# STM32N645 register map
File version: 1.0
CPU: CM55 r0p1, little endian, no MPU, FPU, vendor SysTick, 8 interrupt priority bits
Registers are 32-bit, read-write, reset 0x0 unless marked. A register's access mark holds for its fields unless they carry their own. Offsets are from the block's base; [hi:lo] are bit positions; {n}, {i} and the like mark numbered series.

## HASH — HASH register bank (full SHA-2/SHA-3)
Base 0x44020400
Same registers: HASH_S 0x54020400
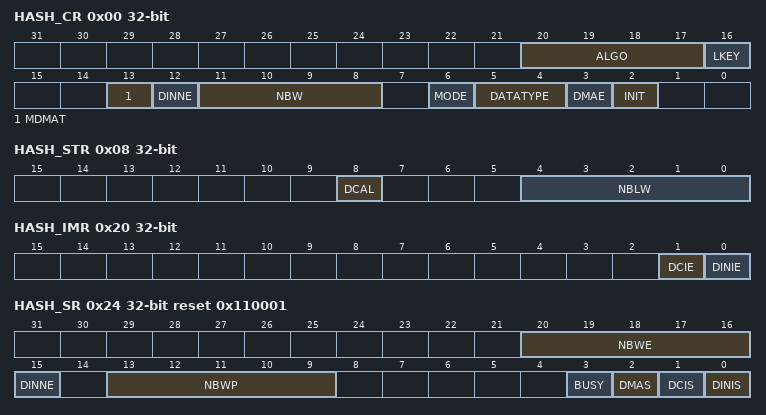
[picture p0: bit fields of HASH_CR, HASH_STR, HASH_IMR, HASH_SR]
0x00 HASH_CR access per field — HASH control register
  [20:17] ALGO rw — Algorithm selection
    0=SHA-1; 2=SHA2-224; 3=SHA2-256; 12=SHA2-384; 13=SHA2-512/224; 14=SHA2-512/256; 15=SHA2-512
  [16] LKEY rw — Long key selection
    0=HMAC key is shorter or equal to the block size (short key). The actual key value written in HASH_DIN is used during the HMAC computation.; 1=HMAC key is longer than the block size (long key). The hash of the key is used instead of the real key during the HMAC computation.
  [13] MDMAT rw — Multiple DMA transfers
    0=DCAL is automatically set at the end of a DMA transfer; 1=DCAL is not automatically set at the end of a DMA transfer
  [12] DINNE ro — DIN not empty
  [11:8] NBW ro — Number of words already pushed
  [6] MODE rw — Mode selection
    0=Hash mode selected; 1=HMAC mode selected. LKEY bit must be set if the key being used is longer than the algorithm block size.
  [5:4] DATATYPE rw — Data type selection
    0=32-bit data. The data written into HASH_DIN are directly used by the HASH processing, without reordering.; 1=16-bit data or half-word. The data written into HASH_DIN are considered as two half-words, and are swapped before being used by the HASH processing.; 2=8-bit data or bytes. The data written into HASH_DIN are considered as four bytes, and are swapped before being used by the HASH processing.; 3=bit data or bit string. The data written into HASH_DIN are considered as 32 bits (1st bit of the string at position 0), and are swapped before being used by the HASH processing (1st bit of the string at position 31).
  [3] DMAE rw — DMA enable
    0=DMA transfers disabled; 1=DMA transfers enabled. A DMA request is sent as soon as the hash core is ready to receive data.
  [2] INIT rw — Initialize message digest calculation
0x04 HASH_DIN wo — HASH data input register
  [31:0] DATAIN — Data input
0x08 HASH_STR — HASH start register
  [8] DCAL — Digest calculation
  [4:0] NBLW — Number of valid bits in the last word
    0=All the 32 bits of the last data written are valid message bits, that is M[31:0]; 1=Only one bit of the last data written (after swapping) is valid, that is M[0]; 2=Only two bits of the last data written (after swapping) are valid, that is M[1:0]; 3=Only three bits of the last data written (after swapping) are valid that is M[2:0]; 31=Only 31 bits of the last data written (after swapping) are valid that is M[30:0]
{0xC+4i} HASH_HRA{i} ro (i=0..4) — HASH aliased digest register {i}
  [31:0] H{i} — Hash data x
0x20 HASH_IMR — HASH interrupt enable register
  [1] DCIE — Digest calculation completion interrupt enable
    0=Digest calculation completion interrupt disabled; 1=Digest calculation completion interrupt enabled
  [0] DINIE — Data input interrupt enable
    0=Data input interrupt disabled; 1=Data input interrupt enabled
0x24 HASH_SR access per field reset 0x110001 — HASH status register
  [20:16] NBWE ro — Number of words expected
  [15] DINNE ro — DIN not empty
    0=No data are present in the data input buffer; 1=The input buffer contains at least one word of data
  [13:9] NBWP ro — Number of words already pushed
  [3] BUSY ro — Busy bit
    0=No block is currently being processed; 1=The hash core is processing a block of data
  [2] DMAS ro — DMA Status
    0=DMA interface is disabled (DMAE = 0) and no transfer is ongoing; 1=DMA interface is enabled (DMAE = 1) or a transfer is ongoing
  [1] DCIS rw — Digest calculation completion interrupt status
    0=No digest available in the HASH_HRx registers (zeros are returned); 1=Digest calculation complete, a digest is available in the HASH_HRx registers. An interrupt is generated if the DCIE bit is set in the HASH_IMR register.
  [0] DINIS rw — Data input interrupt status
    0=Less than 16 locations are free in the input buffer; 1=A new block can be entered into the input buffer. An interrupt is generated if the DINIE bit is set in the HASH_IMR register.
{0xF8+4i} HASH_CSR{i} (i=0..102) — HASH context swap register {i}
  [31:0] CS{i} — Context swap x
{0x310+4i} HASH_HR{i} ro (i=0..4) — HASH digest register {i}
  [31:0] H{i} — Hash data x
{0x310+4i} HASH_HR{i} ro (i=5..15) — HASH supplementary digest register {i}
  [31:0] H{i} — Hash data x
